# R7FA2L209 register map
Vendor: Renesas Electronics Corporation; Series: RA2; File version: 1.10.02
CPU: CM23 r1p0, little endian, MPU, no FPU, VTOR, 2 interrupt priority bits, 32 interrupts
Registers are 8-bit, read-write, reset 0x0 unless marked. A register's access mark holds for its fields unless they carry their own. Offsets are from the block's base; [hi:lo] are bit positions; {n}, {i} and the like mark numbered series; 'fields as' and 'values as' point back to an identical list.

## MSTP — Module Stop Control B, C, D
Base 0x40047000
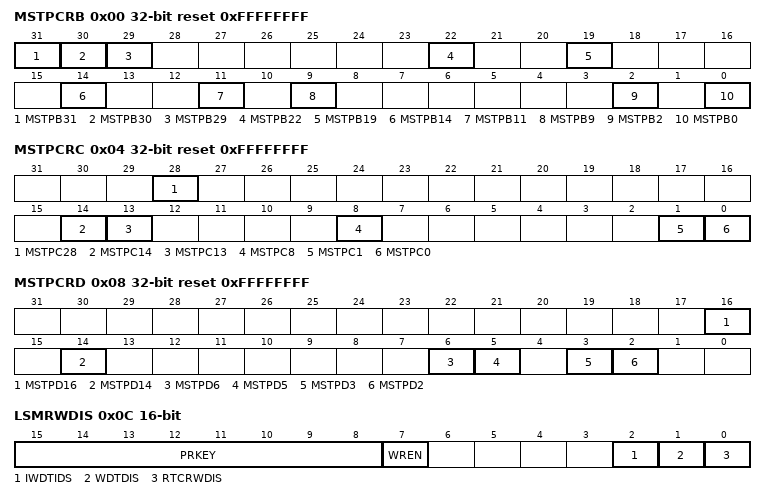
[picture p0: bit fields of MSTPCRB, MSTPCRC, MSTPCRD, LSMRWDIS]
0x00 MSTPCRB 32-bit reset 0xFFFFFFFF — Module Stop Control Register B
  [all] fields
    0=Cancel the module-stop state; 1=Enter the module-stop state
  [31] MSTPB31 — Serial Communication Interface 0 Module Stop
  [30] MSTPB30 — Serial Communication Interface 1 Module Stop
  [29] MSTPB29 — Serial Communication Interface 2 Module Stop
  [22] MSTPB22 — Serial Communication Interface 9 Module Stop
  [19] MSTPB19 — Serial Peripheral Interface 0 Module Stop
  [14] MSTPB14 — Universal Serial Bus Type-C Controller Interface Module Stop
  [11] MSTPB11 — Universal Serial Bus 2.0 FS Interface Module Stop
  [9] MSTPB9 — IIC/I3C Bus Interface 0 Module Stop
  [2] MSTPB2 — Controller Area Network Module Stop
  [0] MSTPB0 — Serial Interface UARTA Module Stop
0x04 MSTPCRC 32-bit reset 0xFFFFFFFF — Module Stop Control Register C
  [all] fields
    values as the fields of MSTPCRB
  [28] MSTPC28 — True Random Number Generator Module Stop
  [14] MSTPC14 — Event Link Controller Module Stop
  [13] MSTPC13 — Data Operation Circuit Module Stop
  [8] MSTPC8 — Serial Sound Interface Enhanced Module Stop
  [1] MSTPC1 — Cyclic Redundancy Check Calculator Module Stop
  [0] MSTPC0 — Clock Frequency Accuracy Measurement Circuit Module Stop
0x08 MSTPCRD 32-bit reset 0xFFFFFFFF — Module Stop Control Register D
  [all] fields
    values as the fields of MSTPCRB
  [16] MSTPD16 — 12-bit A/D Converter Module Stop
  [14] MSTPD14 — Port Output Enable for GPT Module Stop
  [6] MSTPD6 — General PWM Timer 164 to 169 and PWM Delay Generation Circuit Module Stop
  [5] MSTPD5 — General PWM Timer 32n Module Stop
  [3] MSTPD3 — Low Power Asynchronous General Purpose Timer 0 Module Stop
  [2] MSTPD2 — Low Power Asynchronous General Purpose Timer 1 Module Stop
0x0C LSMRWDIS 16-bit — Low Speed Module R/W Disable Control Register
  [15:8] PRKEY wo — LSMRWDIS Key Code
  [7] WREN — Write Enable for bits [2:0]
    0=Write protect for bits [2:0]; 1=Write enable for bits [2:0]
  [2] IWDTIDS — IWDT Register Clock Control
    0=IWDT operates as normal; 1=Stop the IWDT register R/W clock
  [1] WDTDIS — WDT Operate Clock Control
    0=WDT operates as normal; 1=Stop the WDT clock and register R/W clock
  [0] RTCRWDIS — RTC Register R/W Enable Control
    0=RTC register R/W clock always on; 1=RTC register R/W clock stops

## DOC — Data Operation Circuit
Base 0x40054100
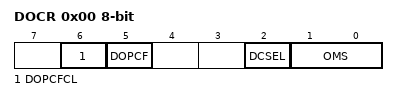
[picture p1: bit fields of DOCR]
0x00 DOCR — DOC Control Register
  [6] DOPCFCL — DOPCF Clear
    0=Retain DOPCF flag state; 1=Clear DOPCF flag
  [5] DOPCF ro — DOC Flag
  [2] DCSEL — Detection Condition Select
    0=Set DOPCF flag when data mismatch is detected; 1=Set DOPCF flag when data match is detected
  [1:0] OMS — Operating Mode Select
    0=Data comparison mode; 1=Data addition mode; 2=Data subtraction mode; 3=Setting prohibited
0x02 DODIR 16-bit — DOC Data Input Register
0x04 DODSR 16-bit — DOC Data Setting Register

## CRC — Cyclic Redundancy Check Calculator
Base 0x40074000
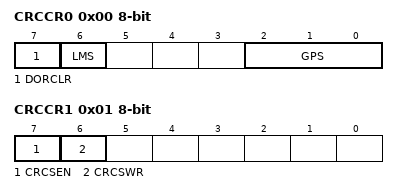
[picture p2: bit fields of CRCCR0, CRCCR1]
0x00 CRCCR0 — CRC Control Register 0
  [7] DORCLR wo — CRCDOR/CRCDOR_HA/CRCDOR_BY Register Clear
    0=No effect; 1=Clear the CRCDOR/CRCDOR_HA/CRCDOR_BY register
  [6] LMS — CRC Calculation Switching
    0=Generate CRC code for LSB-first communication; 1=Generate CRC code for MSB-first communication
  [2:0] GPS — CRC Generating Polynomial Switching
    1=8-bit CRC-8 (X8 + X2 + X + 1); 2=16-bit CRC-16 (X16 + X15 + X2 + 1); 3=16-bit CRC-CCITT (X16 + X12 + X5 + 1); 4=32-bit CRC-32 (X32 + X26 + X23 + X22 + X16 + X12 + X11 +X10 + X8 + X7 + X5 + X4 + X2 + X + 1); 5=32-bit CRC-32C (X32 + X28 + X27 + X26 + X25 + X23 + X22 + X20 + X19 + X18 + X14 + X13 + X11 + X10 + X9 + X8 + X6 + 1); other=Others (No calculation is executed)
0x01 CRCCR1 — CRC Control Register 1
  [7] CRCSEN — Snoop Enable
    0=Disabled; 1=Enabled
  [6] CRCSWR — Snoop-On-Write/Read Switch
    0=Snoop-on-read; 1=Snoop-on-write
0x04 CRCDIR 32-bit — CRC Data Input Register
0x04 CRCDIR_BY (alternate view of CRCDIR) — CRC Data Input Register
0x08 CRCDOR 32-bit — CRC Data Output Register
0x08 CRCDOR_HA 16-bit (alternate view of CRCDOR) — CRC Data Output Register
0x08 CRCDOR_BY (alternate view of CRCDOR) — CRC Data Output Register
0x0C CRCSAR 16-bit — Snoop Address Register
  [13:0] CRCSA — Register Snoop Address

## GPT_OPS — Output Phase Switching Controller
Base 0x40078FF0
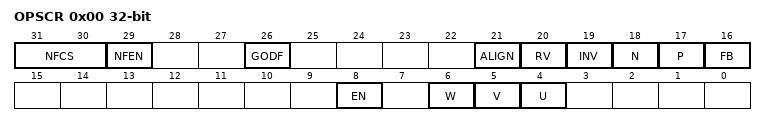
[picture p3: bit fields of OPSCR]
0x00 OPSCR 32-bit — Output Phase Switching Control Register
  [31:30] NFCS — External Input Noise Filter Clock Selection
    0=PCLKD/1; 1=PCLKD/4; 2=PCLKD/16; 3=PCLKD/64
  [29] NFEN — External Input Noise Filter Enable
    0=Do not use a noise filter on the external input; 1=Use a noise filter on the external input
  [26] GODF — Group Output Disable Function
    0=This bit function is ignored; 1=Group disable clears the OPSCR.EN bit
  [21] ALIGN — Input Phase Alignment
    0=Input phase aligned to PCLKD; 1=Input phase aligned to the falling edge of PWM
  [20] RV — Output Phase Rotation Direction Reversal Control
    0=Positive rotation; 1=Reverse rotation
  [19] INV — Output Phase Invert Control
    0=Positive logic (active-high) output; 1=Negative logic (active-low) output
  [18] N — Negative-Phase Output (N) Control
    0=Level signal output; 1=PWM signal output
  [17] P — Positive-Phase Output (P) Control
    0=Level signal output; 1=PWM signal output
  [16] FB — External Feedback Signal Enable
    0=Select the external input; 1=Select the soft setting (OPSCR., , )
  [8] EN — Output Phase Enable
    0=Do not output (Hi-Z external pin); 1=Output
  [6] W ro — Input W-Phase Monitor
  [5] V ro — Input V-Phase Monitor
  [4] U ro — Input U-Phase Monitor

## KINT — Key Interrupt Function
Base 0x40080000
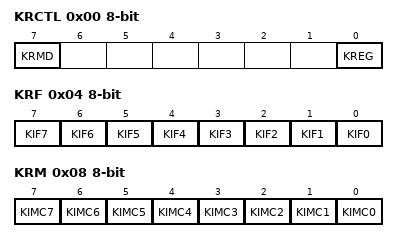
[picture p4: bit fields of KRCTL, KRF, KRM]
0x00 KRCTL — Key Return Control Register
  [7] KRMD — Usage of Key Interrupt Flags (KRF.KIF0 to KRF.KIF7)
    0=Do not use key interrupt flags; 1=Use key interrupt flags
  [0] KREG — Detection Edge Selection (KR00 to KR07 pins)
    0=Falling edge; 1=Rising edge
0x04 KRF — Key Return Flag Register
  [all] fields
    0=No interrupt detected; 1=Interrupt detected
  [n] KIF{n} (n=0..7) — Key Interrupt Flag n
0x08 KRM — Key Return Mode Register
  [all] fields
    0=Do not detect key interrupt signals; 1=Detect key interrupt signals
  [n] KIMC{n} (n=0..7) — Key Interrupt Mode Control n
